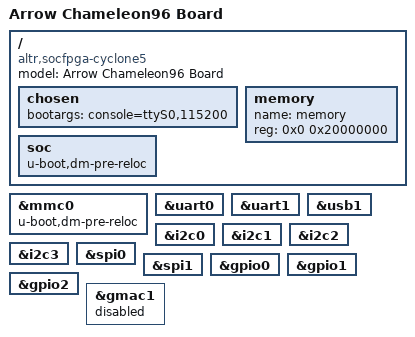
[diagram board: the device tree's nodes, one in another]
/*
 * Copyright Arrow Electronics, Inc. (C) 2017
 *
 * SPDX-License-Identifier:	GPL-2.0+
 */

#include "socfpga_cyclone5.dtsi"

/ {
	model = "Arrow Chameleon96 Board";
	compatible = "altr,socfpga-cyclone5", "altr,socfpga";

	chosen {
		bootargs = "console=ttyS0,115200";
	};

	memory {
		name = "memory";
		device_type = "memory";
		reg = <0x0 0x20000000>; /* 512MB */
	};

	soc {
		u-boot,dm-pre-reloc;
	};
		
};

&mmc0 {
	status = "okay";
	u-boot,dm-pre-reloc;
};

&uart0 {
	status = "okay";
};

&uart1 {
	status = "okay";
};

&usb1 {
	status = "okay";
};

&i2c0 {
	status = "okay";
};

&i2c1 {
	status = "okay";
};

&i2c2 {
	status = "okay";
};

&i2c3 {
	status = "okay";
};

&spi0 {
	status = "okay";
};

&spi1 {
	status = "okay";
};

&gpio0 {
	status = "okay";
};

&gpio1 {
	status = "okay";
};

&gpio2 {
	status = "okay";
};

//enabled in socfpga_cyclone5.dtsi
&gmac1 {
	status = "disabled";
};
